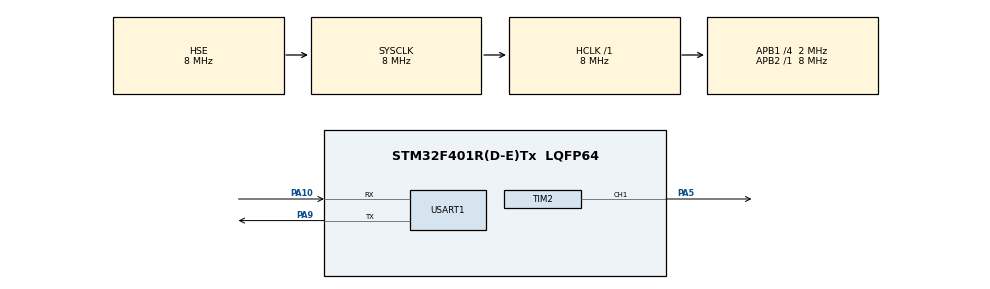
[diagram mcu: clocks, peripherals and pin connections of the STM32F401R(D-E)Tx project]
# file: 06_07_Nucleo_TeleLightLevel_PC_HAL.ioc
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Mcu.Family=STM32F4
Mcu.Name=STM32F401R(D-E)Tx
Mcu.Package=LQFP64
NVIC.PriorityGroup=NVIC_PRIORITYGROUP_4
PA10.Mode=Asynchronous
PA10.Signal=USART1_RX
PA5.Signal=S_TIM2_CH1_ETR
PA9.Mode=Asynchronous
PA9.Signal=USART1_TX
PH0\ -\ OSC_IN.Mode=HSE-External-Oscillator
PH0\ -\ OSC_IN.Signal=RCC_OSC_IN
PH1\ -\ OSC_OUT.Mode=HSE-External-Oscillator
PH1\ -\ OSC_OUT.Signal=RCC_OSC_OUT
ProjectManager.HeapSize=0x200
ProjectManager.StackSize=0x400
ProjectManager.TargetToolchain=STM32CubeIDE
RCC.48MHZClocksFreq_Value=24000000
RCC.AHBFreq_Value=8000000
RCC.APB1CLKDivider=RCC_HCLK_DIV4
RCC.APB1Freq_Value=2000000
RCC.APB1TimFreq_Value=4000000
RCC.APB2Freq_Value=8000000
RCC.APB2TimFreq_Value=8000000
RCC.CortexFreq_Value=8000000
RCC.HCLKFreq_Value=8000000
RCC.HSE_VALUE=8000000
RCC.HSI_VALUE=16000000
RCC.LSE_VALUE=32768
RCC.PLLSourceVirtual=RCC_PLLSOURCE_HSE
RCC.SYSCLKFreq_VALUE=8000000
RCC.SYSCLKSource=RCC_SYSCLKSOURCE_HSE
RCC.VCOOutputFreq_Value=96000000
SH.S_TIM2_CH1_ETR.0=TIM2_CH1,PWM Generation1 CH1
TIM2.Channel-PWM\ Generation1\ CH1=TIM_CHANNEL_1
TIM2.Period=100
USART1.VirtualMode=VM_ASYNC
board=custom

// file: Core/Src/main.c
/* USER CODE BEGIN Header */
/**
  ******************************************************************************
  * @file           : main.c
  * @brief          : Main program body
  ******************************************************************************
  * @attention
  *
  * Copyright (c) 2025 STMicroelectronics.
  * All rights reserved.
  *
  * This software is licensed under terms that can be found in the LICENSE file
  * in the root directory of this software component.
  * If no LICENSE file comes with this software, it is provided AS-IS.
  *
  ******************************************************************************
  */
/* USER CODE END Header */
#include "main.h"

TIM_HandleTypeDef htim2;

UART_HandleTypeDef huart1;

void SystemClock_Config(void);
static void MX_GPIO_Init(void);
static void MX_TIM2_Init(void);
static void MX_USART1_UART_Init(void);

int main(void)
{

  /* USER CODE BEGIN 1 */
  uint8_t duty = 0;
  /* USER CODE END 1 */

  /* MCU Configuration--------------------------------------------------------*/

  /* Reset of all peripherals, Initializes the Flash interface and the Systick. */
  HAL_Init();

  /* Configure the system clock */
  SystemClock_Config();

  /* Initialize all configured peripherals */
  MX_GPIO_Init();
  MX_TIM2_Init();
  MX_USART1_UART_Init();
  /* USER CODE BEGIN 2 */
  TIM2->CCR1 = duty;
  HAL_TIM_PWM_Start(&htim2, TIM_CHANNEL_1);

  /* USER CODE END 2 */

  /* Infinite loop */
  /* USER CODE BEGIN WHILE */
  while (1)
  {

	  HAL_UART_Receive(&huart1, &duty, 1, 20);
	  TIM2->CCR1 = duty;

    /* USER CODE END WHILE */

  }
}

void SystemClock_Config(void)
{
  RCC_OscInitTypeDef RCC_OscInitStruct = {0};
  RCC_ClkInitTypeDef RCC_ClkInitStruct = {0};

  /** Configure the main internal regulator output voltage
  */
  __HAL_RCC_PWR_CLK_ENABLE();
  __HAL_PWR_VOLTAGESCALING_CONFIG(PWR_REGULATOR_VOLTAGE_SCALE2);

  /** Initializes the RCC Oscillators according to the specified parameters
  * in the RCC_OscInitTypeDef structure.
  */
  RCC_OscInitStruct.OscillatorType = RCC_OSCILLATORTYPE_HSE;
  RCC_OscInitStruct.HSEState = RCC_HSE_ON;
  RCC_OscInitStruct.PLL.PLLState = RCC_PLL_NONE;
  if (HAL_RCC_OscConfig(&RCC_OscInitStruct) != HAL_OK)
  {
    Error_Handler();
  }

  /** Initializes the CPU, AHB and APB buses clocks
  */
  RCC_ClkInitStruct.ClockType = RCC_CLOCKTYPE_HCLK|RCC_CLOCKTYPE_SYSCLK
                              |RCC_CLOCKTYPE_PCLK1|RCC_CLOCKTYPE_PCLK2;
  RCC_ClkInitStruct.SYSCLKSource = RCC_SYSCLKSOURCE_HSE;
  RCC_ClkInitStruct.AHBCLKDivider = RCC_SYSCLK_DIV1;
  RCC_ClkInitStruct.APB1CLKDivider = RCC_HCLK_DIV4;
  RCC_ClkInitStruct.APB2CLKDivider = RCC_HCLK_DIV1;

  if (HAL_RCC_ClockConfig(&RCC_ClkInitStruct, FLASH_LATENCY_0) != HAL_OK)
  {
    Error_Handler();
  }
}

static void MX_TIM2_Init(void)
{

  TIM_MasterConfigTypeDef sMasterConfig = {0};
  TIM_OC_InitTypeDef sConfigOC = {0};

  htim2.Instance = TIM2;
  htim2.Init.Prescaler = 0;
  htim2.Init.CounterMode = TIM_COUNTERMODE_UP;
  htim2.Init.Period = 100;
  htim2.Init.ClockDivision = TIM_CLOCKDIVISION_DIV1;
  htim2.Init.AutoReloadPreload = TIM_AUTORELOAD_PRELOAD_DISABLE;
  if (HAL_TIM_PWM_Init(&htim2) != HAL_OK)
  {
    Error_Handler();
  }
  sMasterConfig.MasterOutputTrigger = TIM_TRGO_RESET;
  sMasterConfig.MasterSlaveMode = TIM_MASTERSLAVEMODE_DISABLE;
  if (HAL_TIMEx_MasterConfigSynchronization(&htim2, &sMasterConfig) != HAL_OK)
  {
    Error_Handler();
  }
  sConfigOC.OCMode = TIM_OCMODE_PWM1;
  sConfigOC.Pulse = 0;
  sConfigOC.OCPolarity = TIM_OCPOLARITY_HIGH;
  sConfigOC.OCFastMode = TIM_OCFAST_DISABLE;
  if (HAL_TIM_PWM_ConfigChannel(&htim2, &sConfigOC, TIM_CHANNEL_1) != HAL_OK)
  {
    Error_Handler();
  }
  HAL_TIM_MspPostInit(&htim2);

}

static void MX_USART1_UART_Init(void)
{

  huart1.Instance = USART1;
  huart1.Init.BaudRate = 115200;
  huart1.Init.WordLength = UART_WORDLENGTH_8B;
  huart1.Init.StopBits = UART_STOPBITS_1;
  huart1.Init.Parity = UART_PARITY_NONE;
  huart1.Init.Mode = UART_MODE_TX_RX;
  huart1.Init.HwFlowCtl = UART_HWCONTROL_NONE;
  huart1.Init.OverSampling = UART_OVERSAMPLING_16;
  if (HAL_UART_Init(&huart1) != HAL_OK)
  {
    Error_Handler();
  }

}

static void MX_GPIO_Init(void)
{

  /* GPIO Ports Clock Enable */
  __HAL_RCC_GPIOH_CLK_ENABLE();
  __HAL_RCC_GPIOA_CLK_ENABLE();

}

void Error_Handler(void)
{
  __disable_irq();
  while (1)
  {
  }
}
